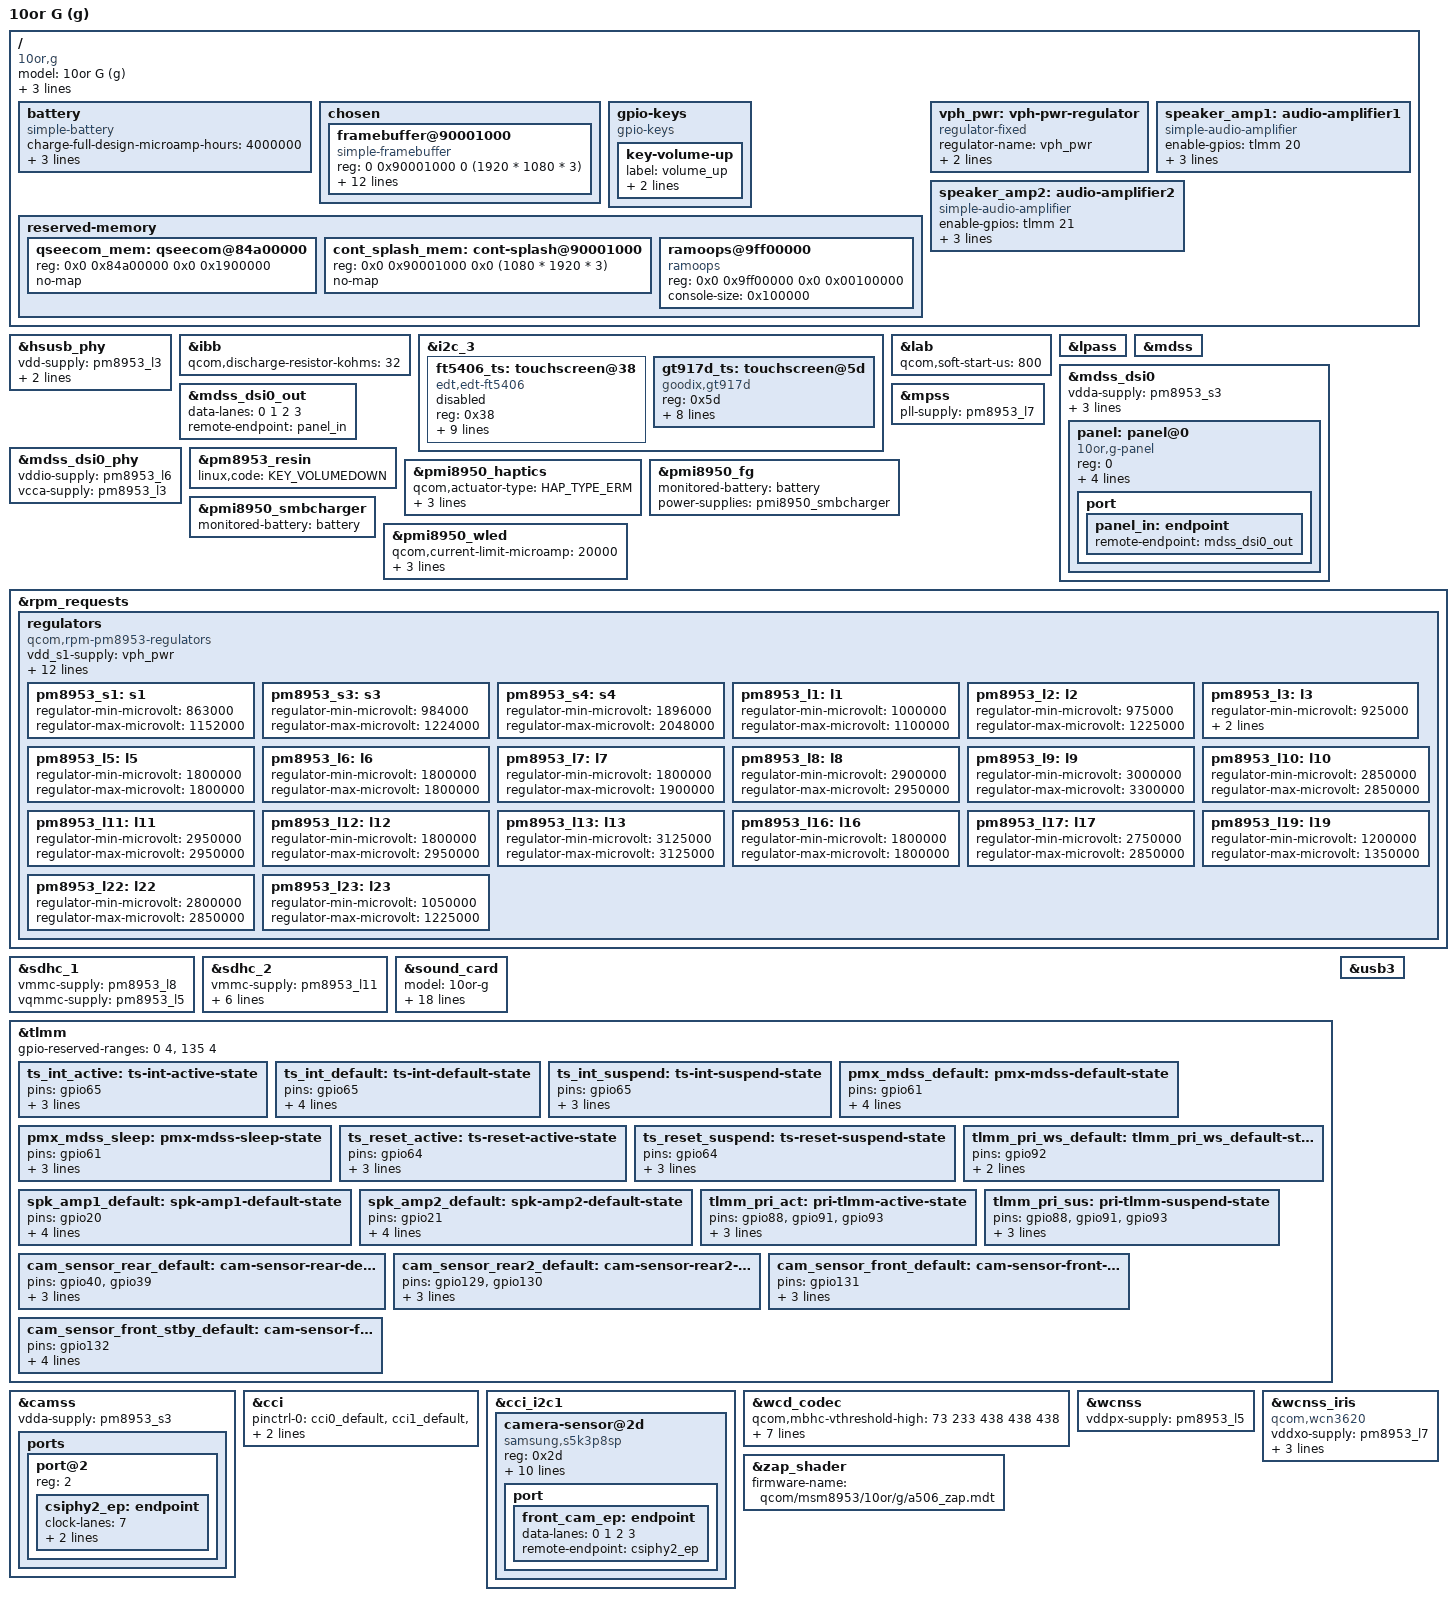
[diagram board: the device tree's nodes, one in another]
// SPDX-License-Identifier: BSD-3-Clause
/*
 * Copyright (c) 2026, Mathesh V <123v.mathesh@gmail.com>
 */
/dts-v1/;

#include "msm8953.dtsi"
#include "pm8953.dtsi"
#include "pmi8950.dtsi"
#include "pmi8950-usb-type-b.dtsi"

/delete-node/ &qseecom_mem;

/ {
	model = "10or G (g)";
	compatible = "10or,g", "qcom,msm8953";
	chassis-type = "handset";
	qcom,msm-id = <293 0x0>;
	qcom,board-id = <0x2000b 0x0>;

	battery: battery {
		compatible = "simple-battery";
		charge-full-design-microamp-hours = <4000000>;
		constant-charge-current-max-microamp = <1000000>;
		voltage-min-design-microvolt = <3400000>;
		voltage-max-design-microvolt = <4400000>;
	};

	chosen {
		#address-cells = <2>;
		#size-cells = <2>;
		ranges;

		framebuffer@90001000 {
			compatible = "simple-framebuffer";
			reg = <0 0x90001000 0 (1920 * 1080 * 3)>;

			width = <1080>;
			height = <1920>;
			stride = <(1080 * 3)>;
			format = "r8g8b8";

			power-domains = <&gcc MDSS_GDSC>;
			
			clocks = <&gcc GCC_MDSS_AHB_CLK>,
				 <&gcc GCC_MDSS_AXI_CLK>,
				 <&gcc GCC_MDSS_VSYNC_CLK>,
				 <&gcc GCC_MDSS_MDP_CLK>,
				 <&gcc GCC_MDSS_BYTE0_CLK>,
				 <&gcc GCC_MDSS_PCLK0_CLK>,
				 <&gcc GCC_MDSS_ESC0_CLK>;
		};
	};
	
	gpio-keys {
		compatible = "gpio-keys";

		key-volume-up {
			label = "volume_up";
			linux,code = <KEY_VOLUMEUP>;
			gpios = <&tlmm 85 GPIO_ACTIVE_LOW>;
		};
	};

	reserved-memory {
		qseecom_mem: qseecom@84a00000 {
			reg = <0x0 0x84a00000 0x0 0x1900000>;
			no-map;
		};

		cont_splash_mem: cont-splash@90001000 {
			reg = <0x0 0x90001000 0x0 (1080 * 1920 * 3)>;
			no-map;
		};

		ramoops@9ff00000 {
			compatible = "ramoops";
			reg = <0x0 0x9ff00000 0x0 0x00100000>;
			console-size = <0x100000>;
		};
	};

	vph_pwr: vph-pwr-regulator {
		compatible = "regulator-fixed";
		regulator-name = "vph_pwr";
		regulator-always-on;
		regulator-boot-on;
	};

	speaker_amp1: audio-amplifier1 {
		compatible = "simple-audio-amplifier";
		enable-gpios = <&tlmm 20 GPIO_ACTIVE_HIGH>;
		sound-name-prefix = "Speaker Amp 1";
		vcc-supply = <&vph_pwr>;
		pinctrl-names = "default";
		pinctrl-0 = <&spk_amp1_default>;
	};

	speaker_amp2: audio-amplifier2 {
		compatible = "simple-audio-amplifier";
		enable-gpios = <&tlmm 21 GPIO_ACTIVE_HIGH>;
		sound-name-prefix = "Speaker Amp 2";
		vcc-supply = <&vph_pwr>;
		pinctrl-names = "default";
		pinctrl-0 = <&spk_amp2_default>;
	};
};

&hsusb_phy {
	vdd-supply = <&pm8953_l3>;
	vdda-pll-supply = <&pm8953_l7>;
	vdda-phy-dpdm-supply = <&pm8953_l13>;

	status = "okay";
};

&ibb {
	qcom,discharge-resistor-kohms = <32>;
};

&i2c_3 {
	status = "okay";

	ft5406_ts: touchscreen@38 {
		compatible = "edt,edt-ft5406";
		reg = <0x38>;

		interrupt-parent = <&tlmm>;
		interrupts = <65 IRQ_TYPE_EDGE_FALLING>;
		
		pinctrl-names = "default", "sleep";
		pinctrl-0 = <&ts_reset_active &ts_int_active>;
		pinctrl-1 = <&ts_reset_suspend &ts_int_suspend>;

		reset-gpios = <&tlmm 64 GPIO_ACTIVE_LOW>;

		vcc-supply = <&pm8953_l10>;
		iovcc-supply = <&pm8953_l6>;

		touchscreen-size-x = <1080>;
		touchscreen-size-y = <1920>;
		status = "disabled";
	};

	gt917d_ts: touchscreen@5d {
		compatible = "goodix,gt917d";
		reg = <0x5d>;

		interrupt-parent = <&tlmm>;
		interrupts = <65 IRQ_TYPE_EDGE_FALLING>;

		pinctrl-names = "default";
		pinctrl-0 = <&ts_int_default>;

		reset-gpios = <&tlmm 64 GPIO_ACTIVE_HIGH>;

		VDDIO-supply = <&pm8953_l6>;
		AVDD28-supply = <&pm8953_l10>;

		touchscreen-size-x = <1080>;
		touchscreen-size-y = <1920>;
		status = "okay";
	};
};

&lab {
	qcom,soft-start-us = <800>;
};

&lpass {
	status = "okay";
};

&mdss {
	status = "okay";
};

&mdss_dsi0 {
	vdda-supply = <&pm8953_s3>;
	vddio-supply = <&pm8953_l6>;

	pinctrl-0 = <&pmx_mdss_default>;
	pinctrl-1 = <&pmx_mdss_sleep>;
	pinctrl-names = "default", "sleep";

	status = "okay";

	panel: panel@0 {
		compatible = "10or,g-panel";
		reg = <0>;

		backlight = <&pmi8950_wled>;

		reset-gpios = <&tlmm 61 GPIO_ACTIVE_LOW>;

		vsp-supply = <&lab>;
		vsn-supply = <&ibb>;

		port {
			panel_in: endpoint {
				remote-endpoint = <&mdss_dsi0_out>;
			};
		};
	};
};

&mdss_dsi0_out {
	data-lanes = <0 1 2 3>;
	remote-endpoint = <&panel_in>;
};

&mdss_dsi0_phy {
	vddio-supply = <&pm8953_l6>;
	vcca-supply = <&pm8953_l3>;

	status = "okay";
};

&mpss {
	pll-supply = <&pm8953_l7>;

	status = "okay";
};

&pm8953_resin {
	linux,code = <KEY_VOLUMEDOWN>;
	
	status = "okay";
};

&pmi8950_haptics {
	qcom,actuator-type = <HAP_TYPE_ERM>;
	qcom,brake-pattern = <0x3 0x3 0x0 0x0>;
	qcom,wave-play-rate-us = <5263>;
	qcom,wave-shape = <HAP_WAVE_SQUARE>;

	status = "okay";
};

&pmi8950_fg {
	monitored-battery = <&battery>;
	power-supplies = <&pmi8950_smbcharger>;

	status = "okay";
};

&pmi8950_smbcharger {
	monitored-battery = <&battery>;

	status = "okay";
};

&pmi8950_wled {
	qcom,current-limit-microamp = <20000>;
	qcom,num-strings = <2>;
	qcom,external-pfet;
	qcom,cabc;

	status = "okay";
};

&rpm_requests {
	regulators {
		compatible = "qcom,rpm-pm8953-regulators";
		vdd_s1-supply = <&vph_pwr>;
		vdd_s2-supply = <&vph_pwr>;
		vdd_s3-supply = <&vph_pwr>;
		vdd_s4-supply = <&vph_pwr>;
		vdd_s5-supply = <&vph_pwr>;
		vdd_s6-supply = <&vph_pwr>;
		vdd_s7-supply = <&vph_pwr>;
		vdd_l1-supply = <&pm8953_s3>;
		vdd_l2_l3-supply = <&pm8953_s3>;
		vdd_l4_l5_l6_l7_l16_l19-supply = <&pm8953_s4>;
		vdd_l8_l11_l12_l13_l14_l15-supply = <&vph_pwr>;
		vdd_l9_l10_l17_l18_l22-supply = <&vph_pwr>;
		vdd_l23-supply = <&pm8953_s3>;

		pm8953_s1: s1 {
			regulator-min-microvolt = <863000>;
			regulator-max-microvolt = <1152000>;
		};

		pm8953_s3: s3 {
			regulator-min-microvolt = <984000>;
			regulator-max-microvolt = <1224000>;
		};

		pm8953_s4: s4 {
			regulator-min-microvolt = <1896000>;
			regulator-max-microvolt = <2048000>;
		};

		pm8953_l1: l1 {
			regulator-min-microvolt = <1000000>;
			regulator-max-microvolt = <1100000>;
		};

		pm8953_l2: l2 {
			regulator-min-microvolt = <975000>;
			regulator-max-microvolt = <1225000>;
		};

		pm8953_l3: l3 {
			regulator-min-microvolt = <925000>;
			regulator-max-microvolt = <925000>;
			regulator-allow-set-load;
		};

		pm8953_l5: l5 {
			regulator-min-microvolt = <1800000>;
			regulator-max-microvolt = <1800000>;
		};

		pm8953_l6: l6 {
			regulator-min-microvolt = <1800000>;
			regulator-max-microvolt = <1800000>;
		};

		pm8953_l7: l7 {
			regulator-min-microvolt = <1800000>;
			regulator-max-microvolt = <1900000>;
		};

		pm8953_l8: l8 {
			regulator-min-microvolt = <2900000>;
			regulator-max-microvolt = <2950000>;
		};

		pm8953_l9: l9 {
			regulator-min-microvolt = <3000000>;
			regulator-max-microvolt = <3300000>;
		};

		pm8953_l10: l10 {
			regulator-min-microvolt = <2850000>;
			regulator-max-microvolt = <2850000>;
		};

		pm8953_l11: l11 {
			regulator-min-microvolt = <2950000>;
			regulator-max-microvolt = <2950000>;
		};

		pm8953_l12: l12 {
			regulator-min-microvolt = <1800000>;
			regulator-max-microvolt = <2950000>;
		};

		pm8953_l13: l13 {
			regulator-min-microvolt = <3125000>;
			regulator-max-microvolt = <3125000>;
		};

		pm8953_l16: l16 {
			regulator-min-microvolt = <1800000>;
			regulator-max-microvolt = <1800000>;
		};

		pm8953_l17: l17 {
			regulator-min-microvolt = <2750000>;
			regulator-max-microvolt = <2850000>;
		};

		pm8953_l19: l19 {
			regulator-min-microvolt = <1200000>;
			regulator-max-microvolt = <1350000>;
		};

		pm8953_l22: l22 {
			regulator-min-microvolt = <2800000>;
			regulator-max-microvolt = <2850000>;
		};

		pm8953_l23: l23 {
			regulator-min-microvolt = <1050000>;
			regulator-max-microvolt = <1225000>;
		};
	};
};

&sdhc_1 {
	vmmc-supply = <&pm8953_l8>;
	vqmmc-supply = <&pm8953_l5>;

	status = "okay";
};

&sdhc_2 {
	vmmc-supply = <&pm8953_l11>;
	vqmmc-supply = <&pm8953_l12>;

	cd-gpios = <&tlmm 133 GPIO_ACTIVE_LOW>;

	pinctrl-0 = <&sdc2_clk_on &sdc2_cmd_on &sdc2_data_on &sdc2_cd_off>;
	pinctrl-1 = <&sdc2_clk_off &sdc2_cmd_off &sdc2_data_off &sdc2_cd_off>;
	pinctrl-names = "default", "sleep";

	status = "okay";
};

&sound_card {
	model = "10or-g";

	aux-devs = <&speaker_amp1>, <&speaker_amp2>;
	widgets = "Speaker", "Ext Spk";
	audio-routing =
		"AMIC1", "MIC BIAS External1",
		"AMIC2", "MIC BIAS Internal2",
		"AMIC3", "MIC BIAS External1",
		"MM_DL1", "MultiMedia1 Playback",
		"MM_DL3", "MultiMedia3 Playback",
		"MM_DL4", "MultiMedia4 Playback",
		"MultiMedia2 Capture", "MM_UL2",
		"Speaker Amp 1 INL", "HPH_L",
		"Speaker Amp 2 INL", "HPH_R",
		"Ext Spk", "Speaker Amp 1 OUTL",
		"Ext Spk", "Speaker Amp 2 OUTL";

	pinctrl-names = "default", "sleep";
	pinctrl-0 = <&cdc_pdm_lines_act &cdc_pdm_lines_2_act &cdc_pdm_comp_lines_act &tlmm_pri_act &tlmm_pri_ws_default>;
	pinctrl-1 = <&cdc_pdm_lines_sus &cdc_pdm_lines_2_sus &cdc_pdm_comp_lines_sus &tlmm_pri_sus &tlmm_pri_ws_default>;

	status = "okay";
};

&tlmm {
	gpio-reserved-ranges = <0 4>, <135 4>;

	ts_int_active: ts-int-active-state {
		pins = "gpio65";
		function = "gpio";
		drive-strength = <8>;
		bias-pull-up;
	};

	ts_int_default: ts-int-default-state {
		pins = "gpio65";
		function = "gpio";
		drive-strength = <16>;
		input-enable;
		bias-disable;
	};

	ts_int_suspend: ts-int-suspend-state {
		pins = "gpio65";
		function = "gpio";
		drive-strength = <2>;
		bias-pull-down;
	};

	pmx_mdss_default: pmx-mdss-default-state {
		pins = "gpio61";
		function = "gpio";
		drive-strength = <8>;
		bias-disable;
		output-high;
	};

	pmx_mdss_sleep: pmx-mdss-sleep-state {
		pins = "gpio61";
		function = "gpio";
		drive-strength = <2>;
		bias-pull-down;
	};

	ts_reset_active: ts-reset-active-state {
		pins = "gpio64";
		function = "gpio";
		drive-strength = <8>;
		bias-pull-up;
	};

	ts_reset_suspend: ts-reset-suspend-state {
		pins = "gpio64";
		function = "gpio";
		drive-strength = <2>;
		bias-pull-down;
	};

	tlmm_pri_ws_default: tlmm_pri_ws_default-state {
		pins = "gpio92";
		function = "pri_mi2s_ws";
		drive-strength = <8>;
	};

	spk_amp1_default: spk-amp1-default-state {
		pins = "gpio20";
		function = "gpio";
		drive-strength = <2>;
		bias-pull-down;
		output-low;
	};

	spk_amp2_default: spk-amp2-default-state {
		pins = "gpio21";
		function = "gpio";
		drive-strength = <2>;
		bias-pull-down;
		output-low;
	};

	tlmm_pri_act: pri-tlmm-active-state {
		pins = "gpio88", "gpio91", "gpio93";
		function = "pri_mi2s";
		drive-strength = <8>;
		bias-disable;
	};

	tlmm_pri_sus: pri-tlmm-suspend-state {
		pins = "gpio88", "gpio91", "gpio93";
		function = "pri_mi2s";
		drive-strength = <2>;
		bias-pull-down;
	};

	cam_sensor_rear_default: cam-sensor-rear-default-state {
		pins = "gpio40", "gpio39";
		function = "gpio";
		drive-strength = <2>;
		bias-disable;
	};

	cam_sensor_rear2_default: cam-sensor-rear2-default-state {
		pins = "gpio129", "gpio130";
		function = "gpio";
		drive-strength = <2>;
		bias-disable;
	};

	cam_sensor_front_default: cam-sensor-front-default-state {
		pins = "gpio131";
		function = "gpio";
		drive-strength = <2>;
		bias-disable;
	};

	cam_sensor_front_stby_default: cam-sensor-front-stby-default-state {
		pins = "gpio132";
		function = "gpio";
		drive-strength = <2>;
		bias-disable;
		output-high;
	};
};

&camss {
	status = "okay";
	vdda-supply = <&pm8953_s3>;

	ports {
		port@2 {
			reg = <2>;
			csiphy2_ep: endpoint {
				clock-lanes = <7>;
				data-lanes = <0 1 2 3>;
				remote-endpoint = <&front_cam_ep>;
			};
		};
	};
};

&cci {
	pinctrl-names = "default";
	pinctrl-0 = <&cci0_default>,
		    <&cci1_default>,
		    <&camss_mclk0_default>,
		    <&camss_mclk1_default>,
		    <&camss_mclk2_default>;

	status = "okay";
};



&cci_i2c1 {
	/* Rear Primary Camera - OV13855 (13MP) */
	/* Connected to CSIPHY0, MCLK0 (gpio26) */
	/* Missing mainline driver for OV13855 */

	/* Front Camera - S5K3P8SP (16MP) */
	camera-sensor@2d {
		compatible = "samsung,s5k3p8sp";
		reg = <0x2d>;

		clocks = <&gcc GCC_CAMSS_MCLK1_CLK>;
		clock-frequency = <24000000>;

		pinctrl-names = "default";
		pinctrl-0 = <&cam_sensor_front_default>, <&cam_sensor_front_stby_default>;

		reset-gpios = <&tlmm 131 GPIO_ACTIVE_LOW>;
		/* Standby managed by driver or shared default state usually */

		avdd-supply = <&pm8953_l22>;
		dvdd-supply = <&pm8953_l23>;
		vio-supply = <&pm8953_l6>;

		rotation = <270>;
		orientation = <0>;

		status = "okay";

		port {
			front_cam_ep: endpoint {
				data-lanes = <0 1 2 3>;
				remote-endpoint = <&csiphy2_ep>;
			};
		};
	};
};

&usb3 {
	status = "okay";
};

&wcd_codec {
	qcom,mbhc-vthreshold-high = <73 233 438 438 438>;
	qcom,mbhc-vthreshold-low = <73 233 438 438 438>;
	qcom,micbias1-ext-cap;
	qcom,hphl-jack-type-normally-open;
	qcom,gnd-jack-type-normally-open;

	vdd-cdc-io-supply = <&pm8953_l5>;
	vdd-cdc-tx-rx-cx-supply = <&pm8953_s4>;
	vdd-micbias-supply = <&pm8953_l13>;
	
	status = "okay";
};

&wcnss {
	vddpx-supply = <&pm8953_l5>;

	status = "okay";
};

&wcnss_iris {
	compatible = "qcom,wcn3620";

	vddxo-supply = <&pm8953_l7>;
	vddrfa-supply = <&pm8953_l19>;
	vddpa-supply = <&pm8953_l9>;
	vdddig-supply = <&pm8953_l5>;
};

&zap_shader {
	firmware-name = "qcom/msm8953/10or/g/a506_zap.mdt";
};
